# STM32WL3xx register map
File version: 1.0
Registers are 32-bit, read-write, reset 0x0 unless marked. A register's access mark holds for its fields unless they carry their own. Offsets are from the block's base; [hi:lo] are bit positions; {n}, {i} and the like mark numbered series; 'fields as' and 'values as' point back to an identical list.

## PWR — Power control (PWR)
Base 0x48500000
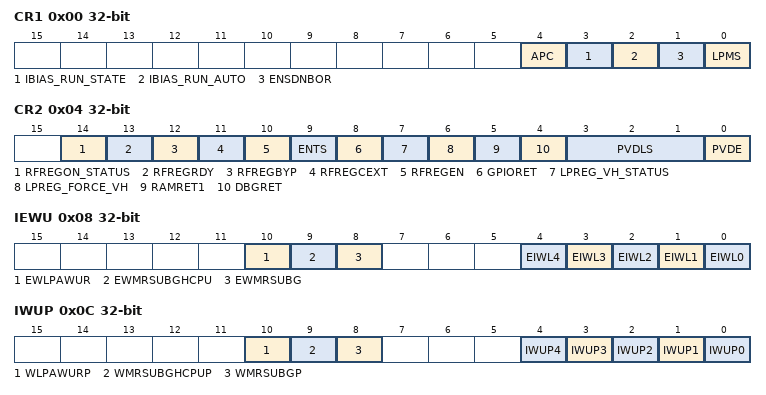
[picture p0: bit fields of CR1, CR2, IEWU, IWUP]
0x00 CR1 — (@ 0x00000000) CR1 register
  [4] APC
  [3] IBIAS_RUN_STATE
  [2] IBIAS_RUN_AUTO
  [1] ENSDNBOR
  [0] LPMS
    0=DEEPSTOP (Low Power Mode Selection DEEPSTOP mode); 1=SHUTDOWN (Low Power Mode Selection SHUTDOWN mode)
0x04 CR2 — (@ 0x00000004) CR2 register
  [14] RFREGON_STATUS
  [13] RFREGRDY
  [12] RFREGBYP
  [11] RFREGCEXT
  [10] RFREGEN
  [9] ENTS
  [8] GPIORET
  [7] LPREG_VH_STATUS
  [6] LPREG_FORCE_VH
  [5] RAMRET1
  [4] DBGRET
  [3:1] PVDLS
    0=PVDLEVEL_0 (VPVD0 around 2.0 V); 1=PVDLEVEL_1 (VPVD1 around 2.2 V); 2=PVDLEVEL_2 (VPVD2 around 2.4 V); 3=PVDLEVEL_3 (VPVD3 around 2.5 V); 4=PVDLEVEL_4 (VPVD4 around 2.6 V); 5=PVDLEVEL_5 (VPVD5 around 2.8 V); 6=PVDLEVEL_6 (VPVD6 around 2.9 V); 7=PVDLEVEL_7 (External input analog voltage (Compare internally to VBGP))
  [0] PVDE
0x08 IEWU — (@ 0x00000008) IEWU register
  [10] EWLPAWUR, [9] EWMRSUBGHCPU, [8] EWMRSUBG, [n] EIWL{n} (n=0..4)
0x0C IWUP — (@ 0x0000000C) IWUP register
  [10] WLPAWURP, [9] WMRSUBGHCPUP, [8] WMRSUBGP, [n] IWUP{n} (n=0..4)
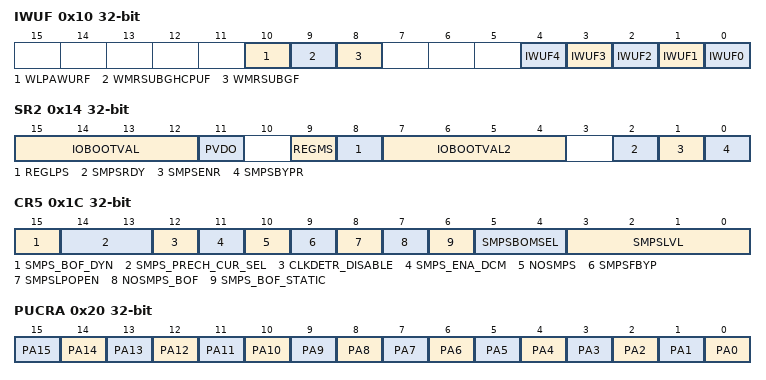
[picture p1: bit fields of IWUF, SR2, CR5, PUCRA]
0x10 IWUF — (@ 0x00000010) IWUF register
  [10] WLPAWURF, [9] WMRSUBGHCPUF, [8] WMRSUBGF, [n] IWUF{n} (n=0..4)
0x14 SR2 — (@ 0x00000014) SR2 register
  [15:12] IOBOOTVAL, [11] PVDO, [9] REGMS, [8] REGLPS, [7:4] IOBOOTVAL2, [2] SMPSRDY, [1] SMPSENR, [0] SMPSBYPR
0x1C CR5 — (@ 0x0000001C) CR5 register
  [15] SMPS_BOF_DYN
  [14:13] SMPS_PRECH_CUR_SEL
    0=CUR_2_5; 1=CUR_5; 2=CUR_10; 3=CUR_20
  [12] CLKDETR_DISABLE
  [11] SMPS_ENA_DCM
  [10] NOSMPS
    0=SMPS (SMPS is enabled); 1=NO_SMPS (SMPS is disabled)
  [9] SMPSFBYP
    0=NO_SMPS_PRECHARGE (SMPS not in pecharge mode); 1=SMPS_PRECHARGE (SMPS is disabled and bypassed in precharge mode)
  [8] SMPSLPOPEN
    0=NO_SMPS_LPOPEN (In DEEPSTOP, the SMPS is in PRECHARGE mode with output connected to VDDIO); 1=SMPS_LPOPEN (In DEEPSTOP, the SMPS is disabled with floating output)
  [7] NOSMPS_BOF
  [6] SMPS_BOF_STATIC
  [5:4] SMPSBOMSEL
    0=BOM1; 1=BOM2; 2=BOM3
  [3:0] SMPSLVL
    0=VOLTAGE_1V20 (0000: 1.20V (min VBAT = 1.95V)); 3=VOLTAGE_1V30 (0011: 1.30V (min VBAT = 1.95V)); 4=VOLTAGE_1V40 (0100: 1.40V (min VBAT = 1.95V) (default)); 5=VOLTAGE_1V50 (0101: 1.50V (min VBAT = 1.95V)); 6=VOLTAGE_1V60 (0110: 1.60V (min VBAT = 1.95V)); 7=VOLTAGE_1V70 (0111: 1.70V (min VBAT = 2V)); 8=VOLTAGE_1V80 (1000: 1.80V (min VBAT = 2.1V)); 9=VOLTAGE_1V90 (1001: 1.90V (min VBAT = 2.2V)); 10=VOLTAGE_2V00 (1010: 2V (min VBAT = 2.3V)); 11=VOLTAGE_2V10 (1011: 2.1V (min VBAT = 2.4V)); 12=VOLTAGE_2V20 (1100: 2.2V (min VBAT = 2.5V)); 13=VOLTAGE_2V30 (1101: 2.3V (min VBAT = 2.6V)); 15=VOLTAGE_2V40 (1111: 2.4V (min VBAT = 2.7V))
0x20 PUCRA — (@ 0x00000020) PUCRA register
  [n] PA{n} (n=0..15)
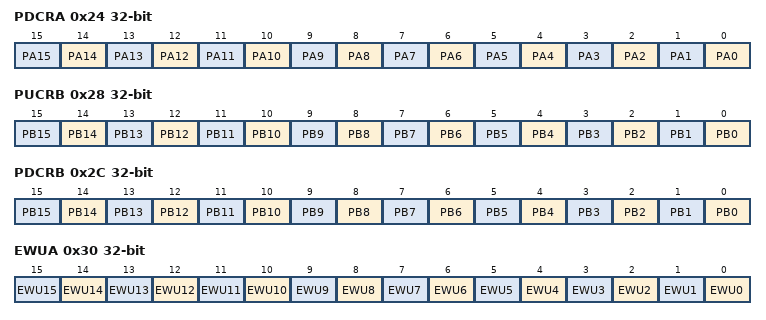
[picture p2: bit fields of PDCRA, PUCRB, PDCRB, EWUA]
0x24 PDCRA — (@ 0x00000024) PDCRA register
  [n] PA{n} (n=0..15)
0x28 PUCRB — (@ 0x00000028) PUCRB register
  [n] PB{n} (n=0..15)
0x2C PDCRB — (@ 0x0000002C) PDCRB register
  [n] PB{n} (n=0..15)
0x30 EWUA — (@ 0x00000030) EWUA register
  [n] EWU{n} (n=0..15)
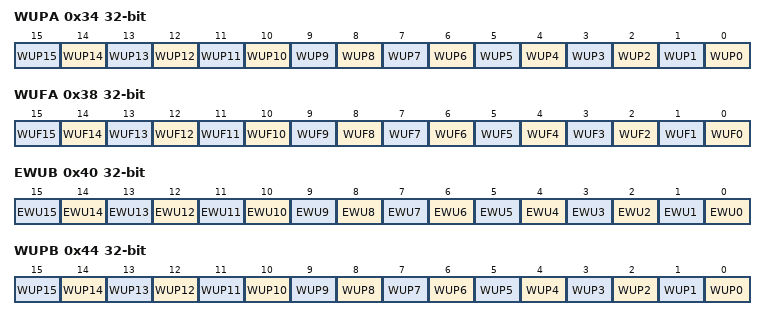
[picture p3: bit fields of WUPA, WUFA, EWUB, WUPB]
0x34 WUPA — (@ 0x00000034) WUPA register
  [n] WUP{n} (n=0..15)
0x38 WUFA — (@ 0x00000038) WUFA register
  [n] WUF{n} (n=0..15)
0x40 EWUB — (@ 0x00000040) EWUB register
  [n] EWU{n} (n=0..15)
0x44 WUPB — (@ 0x00000044) WUPB register
  [n] WUP{n} (n=0..15)
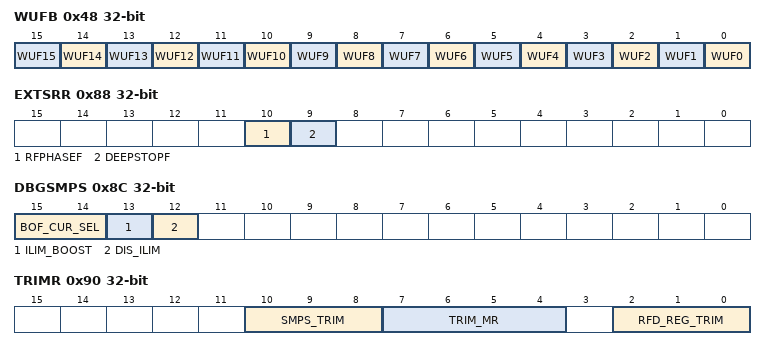
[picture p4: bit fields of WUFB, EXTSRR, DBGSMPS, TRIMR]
0x48 WUFB — (@ 0x00000048) WUFB register
  [n] WUF{n} (n=0..15)
0x4C SDWN_WUEN — (@ 0x0000004C) SDWN_WUEN register
  [0] WUEN
0x50 SDWN_WUPOL — (@ 0x00000050) SDWN_WUPOL register
  [0] WUPOL
0x54 SDWN_WUF — (@ 0x00000054) SDWN_WUF register
  [0] WUF
0x58 BOF_TUNE — (@ 0x00000058) BOF_TUNE register
  [2:0] BOF_TUNE
0x84 DBGR — (@ 0x00000084) DBGR register
  [0] DEEPSTOP2
0x88 EXTSRR — (@ 0x00000088) EXTSRR register
  [10] RFPHASEF, [9] DEEPSTOPF
0x8C DBGSMPS — (@ 0x0000008C) DBGSMPS register
  [15:14] BOF_CUR_SEL, [13] ILIM_BOOST, [12] DIS_ILIM
0x90 TRIMR — (@ 0x00000090) TRIMR register
  [10:8] SMPS_TRIM, [7:4] TRIM_MR, [2:0] RFD_REG_TRIM
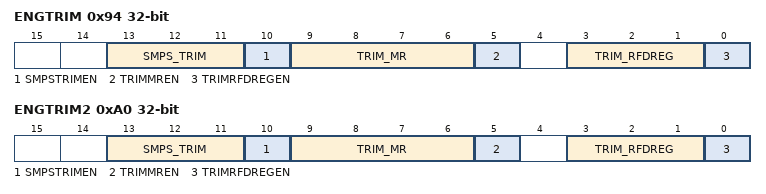
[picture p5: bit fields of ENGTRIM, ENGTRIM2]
0x94 ENGTRIM — (@ 0x00000094) ENGTRIM register
  [13:11] SMPS_TRIM, [10] SMPSTRIMEN, [9:6] TRIM_MR, [5] TRIMMREN, [3:1] TRIM_RFDREG, [0] TRIMRFDREGEN
0xA0 ENGTRIM2 — (@ 0x000000A0) ENGTRIM register
  fields as ENGTRIM
